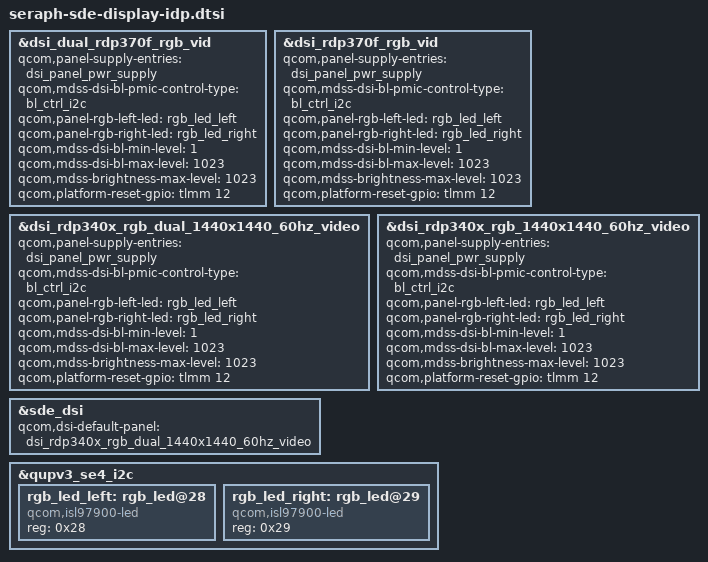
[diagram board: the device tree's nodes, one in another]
#include "seraph-sde-display.dtsi"

&dsi_dual_rdp370f_rgb_vid {
	qcom,panel-supply-entries = <&dsi_panel_pwr_supply>;
	qcom,mdss-dsi-bl-pmic-control-type = "bl_ctrl_i2c";
	qcom,panel-rgb-left-led = <&rgb_led_left>;
	qcom,panel-rgb-right-led = <&rgb_led_right>;
	qcom,mdss-dsi-bl-min-level = <1>;
	qcom,mdss-dsi-bl-max-level = <1023>;
	qcom,mdss-brightness-max-level = <1023>;
	qcom,platform-reset-gpio = <&tlmm 12 0>;
};

&dsi_rdp370f_rgb_vid {
	qcom,panel-supply-entries = <&dsi_panel_pwr_supply>;
	qcom,mdss-dsi-bl-pmic-control-type = "bl_ctrl_i2c";
	qcom,panel-rgb-left-led = <&rgb_led_left>;
	qcom,panel-rgb-right-led = <&rgb_led_right>;
	qcom,mdss-dsi-bl-min-level = <1>;
	qcom,mdss-dsi-bl-max-level = <1023>;
	qcom,mdss-brightness-max-level = <1023>;
	qcom,platform-reset-gpio = <&tlmm 12 0>;
};

&dsi_rdp340x_rgb_dual_1440x1440_60hz_video {
	qcom,panel-supply-entries = <&dsi_panel_pwr_supply>;
	qcom,mdss-dsi-bl-pmic-control-type = "bl_ctrl_i2c";
	qcom,panel-rgb-left-led = <&rgb_led_left>;
	qcom,panel-rgb-right-led = <&rgb_led_right>;
	qcom,mdss-dsi-bl-min-level = <1>;
	qcom,mdss-dsi-bl-max-level = <1023>;
	qcom,mdss-brightness-max-level = <1023>;
	qcom,platform-reset-gpio = <&tlmm 12 0>;
};

&dsi_rdp340x_rgb_1440x1440_60hz_video {
	qcom,panel-supply-entries = <&dsi_panel_pwr_supply>;
	qcom,mdss-dsi-bl-pmic-control-type = "bl_ctrl_i2c";
	qcom,panel-rgb-left-led = <&rgb_led_left>;
	qcom,panel-rgb-right-led = <&rgb_led_right>;
	qcom,mdss-dsi-bl-min-level = <1>;
	qcom,mdss-dsi-bl-max-level = <1023>;
	qcom,mdss-brightness-max-level = <1023>;
	qcom,platform-reset-gpio = <&tlmm 12 0>;
};

&sde_dsi {
	qcom,dsi-default-panel = <&dsi_rdp340x_rgb_dual_1440x1440_60hz_video>;
};

&qupv3_se4_i2c {
	status = "ok";

	rgb_led_left: rgb_led@28 {
		compatible = "qcom,isl97900-led";
		reg = <0x28>;
	};

	rgb_led_right: rgb_led@29 {
		compatible = "qcom,isl97900-led";
		reg = <0x29>;
	};
};
